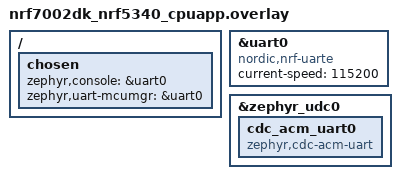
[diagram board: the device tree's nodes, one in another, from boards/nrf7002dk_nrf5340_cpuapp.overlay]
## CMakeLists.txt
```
# SPDX-License-Identifier: Apache-2.0

cmake_minimum_required(VERSION 3.20.0)
find_package(Zephyr REQUIRED HINTS $ENV{ZEPHYR_BASE})
project(central_multilink)

target_sources(app PRIVATE
  src/main.c
  src/listing.c
  src/led_control.c
  src/uart_comm.c
  src/central_multilink.c
)
target_include_directories(app PRIVATE inc)
zephyr_library_include_directories(${ZEPHYR_BASE}/samples/bluetooth)
```

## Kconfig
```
# Copyright (c) 2021 Nordic Semiconductor ASA
# SPDX-License-Identifier: Apache-2.0

mainmenu "Bluetooth: Central Multilink"

config SAMPLE_CONN_ITERATIONS
	int "Connection iterations"
	range 0 255
	default 0
	help
	  Number of times to connect and disconnect to peripheral_identity
	  sample.

source "Kconfig.zephyr"
```

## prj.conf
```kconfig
CONFIG_BT=y
CONFIG_BT_CENTRAL=y
CONFIG_BT_AUTO_PHY_UPDATE=n
CONFIG_BT_PRIVACY=y
CONFIG_BT_OBSERVER=y
CONFIG_BT_MAX_CONN=62
CONFIG_BT_SCAN_WITH_IDENTITY=y
# CONFIG_BT_EXT_ADV=y
# Increase the number of buffers to avoid deadlock when running out of buffers
CONFIG_BT_BUF_CMD_TX_COUNT=2

CONFIG_BT_GATT_CLIENT=y

# CONFIG_BT_SMP=y
# CONFIG_BT_MAX_PAIRED=62

# CONFIG_BT_EXT_ADV=y
# CONFIG_BT_CTLR_ADV_EXT=y

# LED and PWM configuration
CONFIG_PWM=y
CONFIG_LED=y
CONFIG_LED_PWM=y
CONFIG_GPIO=y
CONFIG_DK_LIBRARY=y

# Enable UART driver (existing - for console on UART0)
CONFIG_SERIAL=y
CONFIG_UART_CONSOLE=y
CONFIG_UART_ASYNC_API=y

# USB Device Support (NEW - for nRF5340 USB)
CONFIG_USB_DEVICE_STACK=y
CONFIG_USB_DEVICE_PRODUCT="nRF5340 Sensor Hub"
CONFIG_USB_DEVICE_MANUFACTURER="Your Company"
CONFIG_USB_DEVICE_VID=0x2FE3
CONFIG_USB_DEVICE_PID=0x0001
CONFIG_USB_DEVICE_INITIALIZE_AT_BOOT=y

# USB CDC ACM (NEW)
CONFIG_USB_CDC_ACM=y
CONFIG_UART_LINE_CTRL=y

# Logging (NEW - useful for debugging both interfaces)
CONFIG_LOG=y
CONFIG_PRINTK=y
```

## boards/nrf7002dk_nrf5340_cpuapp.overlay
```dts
/ {
    chosen {
        zephyr,console = &uart0;        // Keep console on UART0
        zephyr,uart-mcumgr = &uart0;
    };
};

&uart0 {
    status = "okay";
    current-speed = <115200>;
    compatible = "nordic,nrf-uarte";
};

&zephyr_udc0 {
    cdc_acm_uart0: cdc_acm_uart0 {
        compatible = "zephyr,cdc-acm-uart";
    };
};
```

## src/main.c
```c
/* main.c - Application main entry point */

/*
 * Copyright (c) 2021 Nordic Semiconductor ASA
 *
 * SPDX-License-Identifier: Apache-2.0
 */

#include <stdint.h>
#include <main.h>

int init_central(uint8_t max_conn, uint8_t iterations);

int main(void)
{
	(void)init_central(CONFIG_BT_MAX_CONN, CONFIG_SAMPLE_CONN_ITERATIONS);
	// Initialize USB CDC ACM
	return 0;
}
```

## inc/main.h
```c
#include <zephyr/types.h>
#include <stdint.h>
#include <stddef.h>
#include <stdbool.h>
#include <errno.h>
#include <string.h>
#include <zephyr/kernel.h>
#include <zephyr/sys/printk.h>

#include <zephyr/bluetooth/bluetooth.h>
#include <zephyr/bluetooth/hci.h>
#include <zephyr/bluetooth/conn.h>
#include <zephyr/bluetooth/uuid.h>
#include <zephyr/bluetooth/gatt.h>
#include <zephyr/sys/byteorder.h>
#include <zephyr/sys/slist.h>
#include <zephyr/drivers/gpio.h>
#include <zephyr/drivers/led.h>
#include <zephyr/device.h>
#include <zephyr/devicetree.h>
#include <dk_buttons_and_leds.h>
#include <zephyr/drivers/uart.h>

/* Environmental Sensing Service UUIDs */
#define BT_UUID_ESS_VAL 0x181a
#define BT_UUID_TEMP_CHAR_VAL     0x2a6e
#define BT_UUID_PRESSURE_CHAR_VAL 0x2a6d
#define BT_UUID_HUMIDITY_CHAR_VAL 0x2a6f

#define SCAN_INTERVAL 0x0010 /* 10 ms */
#define SCAN_WINDOW   0x0010 /* 10 ms */
#define INIT_INTERVAL 0x0010 /* 10 ms */
#define INIT_WINDOW   0x0010 /* 10 ms */
#define CONN_INTERVAL 0x0320 /* 1000 ms */
#define CONN_LATENCY  0
#define CONN_TIMEOUT  MIN(MAX((CONN_INTERVAL * 125 * \
			       MAX(CONFIG_BT_MAX_CONN, 6) / 1000), 10), 3200)

/* LED Configuration */
#define LED_PWM_NODE_ID	 DT_COMPAT_GET_ANY_STATUS_OKAY(pwm_leds)
#define MAX_BRIGHTNESS	100
#define PWM_FADE_DELAY	50
#define BLINK_INTERVAL  2000  /* 2 seconds between blinks */
#define BLINK_DURATION  200   /* 200ms blink duration */
#define CON_STATUS_LED  DK_LED1  /* GPIO LED1 as fallback */

/* Manual Whitelist system */
#define MAX_DEVICE_LIST 200  /* Increased from 50 to handle more devices */
#define MAX_MANUAL_WHITELIST 10  /* Maximum number of manually whitelisted devices */

/* UART */
#define UART_LABEL DT_LABEL(DT_NODELABEL(uart0))
#define MAX_SEEED_CONN 4  // Max number of simultaneous Seeed BLE devices

/* Manual whitelist entry structure */
typedef struct {
    char mac[18];  // "AA:BB:CC:DD:EE:FF\0"
    bool active;
} manual_whitelist_entry_t;

/* Whitelist/Blacklist Structs*/
typedef enum {
	DEVICE_STATUS_UNKNOWN = 0,
	DEVICE_STATUS_WHITELISTED,
	DEVICE_STATUS_BLACKLISTED
} device_status_t;

typedef struct device_entry {
	bt_addr_le_t addr;
	device_status_t status;
	uint8_t disconnect_count;
	uint8_t connect_count;
	uint8_t scan_found_count;
	bool has_made_param_request;
	sys_snode_t node;
} device_entry_t;

/* GATT Client structures for Environmental Sensing Service */
struct gatt_ess_data {
	struct bt_conn *conn;
	uint16_t temp_handle;
	uint16_t pressure_handle;
	uint16_t humidity_handle;
	uint16_t temp_ccc_handle;
	uint16_t pressure_ccc_handle;
	uint16_t humidity_ccc_handle;
	bool temp_notify_enabled;
	bool pressure_notify_enabled;
	bool humidity_notify_enabled;
};

extern struct gatt_ess_data ess_data[CONFIG_BT_MAX_CONN];

/* Packet structure sent over UART */
typedef struct __packed {
    char device_addr[BT_ADDR_LE_STR_LEN];  // Seeed device ID or slot index
    int16_t value_a;
    uint32_t value_b;
    uint16_t value_c;
} sensor_packet_t;

typedef struct __packed {
    char mac_addr[30];   // ASCII MAC string, null-padded
    int8_t rssi;         // signed 8-bit RSSI
    uint8_t connected;   // 1 = connected to this central, 0 = not connected
} rssi_packet_t;

/* Per-connection state */
typedef struct {
    struct bt_conn *conn;
    sensor_packet_t data;
    bool a_ready;
    bool b_ready;
    bool c_ready;
    bool active;
    uint8_t subscribed_mask;  // bitmask of subscribed characteristics (bit0=A, bit1=B, bit2=C)
} seeed_conn_t;



void start_scan(void);
void start_passive_scan(void);
device_status_t get_device_status(const bt_addr_le_t *addr);
void add_device_to_whitelist(const bt_addr_le_t *addr);
void remove_device_from_whitelist(const bt_addr_le_t *addr);
void add_device_to_blacklist(const bt_addr_le_t *addr);
bool is_device_whitelisted(const bt_addr_le_t *addr);
bool is_device_blacklisted(const bt_addr_le_t *addr);
bool is_device_manually_whitelisted(const bt_addr_le_t *addr);
device_entry_t *get_or_create_device_entry(const bt_addr_le_t *addr);
void track_device_connect(const bt_addr_le_t *addr);
void track_device_disconnect(const bt_addr_le_t *addr, uint8_t reason);

/* Manual whitelist management functions */
void init_manual_whitelist(void);
bool add_mac_to_manual_whitelist(const char *mac_str);
bool remove_mac_from_manual_whitelist(const char *mac_str);

/* LED control functions */
void led_work_handler(struct k_work *work);
void led_timer_handler(struct k_timer *timer);
void start_led_breathing(void);
void start_led_blinking(uint8_t device_count);
void stop_led_effects(void);
void flash_data_led(void);

#if defined(CONFIG_BT_GATT_CLIENT) /* GATT Client functions */
extern struct bt_gatt_exchange_params mtu_exchange_params[CONFIG_BT_MAX_CONN];
extern struct bt_gatt_discover_params discover_params[CONFIG_BT_MAX_CONN];
extern struct bt_gatt_subscribe_params subscribe_params[CONFIG_BT_MAX_CONN * 3]; /* 3 characteristics per connection */

void mtu_exchange_cb(struct bt_conn *conn, uint8_t err, struct bt_gatt_exchange_params *params);
int mtu_exchange(struct bt_conn *conn);
uint8_t ess_notify_cb(struct bt_conn *conn, struct bt_gatt_subscribe_params *params, const void *data, uint16_t length);
uint8_t ess_discover_func(struct bt_conn *conn, const struct bt_gatt_attr *attr, struct bt_gatt_discover_params *params);
void ess_discover_complete(struct bt_conn *conn, int err);
int ess_discover_services(struct bt_conn *conn);
int ess_subscribe_notifications(struct bt_conn *conn);
#endif /* CONFIG_BT_GATT_CLIENT */

#if defined(CONFIG_BT_SMP)
void security_changed(struct bt_conn *conn, bt_security_t level, enum bt_security_err err);
#endif

#if defined(CONFIG_BT_USER_PHY_UPDATE)
void le_phy_updated(struct bt_conn *conn, struct bt_conn_le_phy_info *param);
#endif

#if defined(CONFIG_BT_USER_DATA_LEN_UPDATE)
void le_data_len_updated(struct bt_conn *conn, struct bt_conn_le_data_len_info *info);
#endif

/* Central Multilink BLE Functions*/
void connected(struct bt_conn *conn, uint8_t reason);
void disconnected(struct bt_conn *conn, uint8_t reason);
bool app_le_param_req(struct bt_conn *conn, struct bt_le_conn_param *param);
void app_le_param_updated(struct bt_conn *conn, uint16_t interval, uint16_t latency, uint16_t timeout);
void remote_info(struct bt_conn *conn, void *data);
void disconnect(struct bt_conn *conn, void* data);
int init_central(uint8_t max_conn, uint8_t iterations);
extern struct bt_conn_cb conn_callbacks;

/* UART Control Functions */
void uart_send_data(const uint8_t *data, size_t len);
void on_ble_connected(struct bt_conn *conn, char* addr);
void on_ble_disconnected(struct bt_conn *conn);
seeed_conn_t *find_node_by_conn(struct bt_conn *conn);
seeed_conn_t *find_node_by_mac_addr(char* addr);
void try_send_packet(seeed_conn_t *node);
void ble_value_a_received(struct bt_conn *conn, int16_t val);
void ble_value_b_received(struct bt_conn *conn, uint32_t val);
void ble_value_c_received(struct bt_conn *conn, uint16_t val);

/* Whitelist/Blacklist system variables*/
extern sys_slist_t whitelist;
extern sys_slist_t blacklist;
extern device_entry_t device_entries[MAX_DEVICE_LIST];
extern uint8_t device_entry_count;

extern struct bt_conn *conn_connecting;
extern uint8_t conn_count_max;
extern uint8_t volatile conn_count;
extern bool volatile is_disconnecting;

/* Manual whitelist variables */
extern manual_whitelist_entry_t manual_whitelist[MAX_MANUAL_WHITELIST];
extern uint8_t manual_whitelist_count;

/* LED control variables */
extern const struct device *led_pwm;
extern int16_t current_brightness;
extern bool brightness_increasing;
extern struct k_timer led_timer;
extern struct k_work led_work;
extern bool led_blink_state;
extern uint8_t blink_count;

/* UART Variables */
extern const struct device *uart_dev;
extern seeed_conn_t seeed_nodes[MAX_SEEED_CONN];

int usb_init(void);
void usb_send_data(const uint8_t *data, size_t len);
void usb_send_framed(uint8_t type, const uint8_t *payload, size_t len);
void send_rssi_report(const char *mac17, int8_t rssi, uint8_t connected_flag);
```

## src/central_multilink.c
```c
/* main.c - Application main entry point */

/*
 * Copyright (c) 2021 Nordic Semiconductor ASA
 * Copyright (c) 2015-2016 Intel Corporation
 *
 * SPDX-License-Identifier: Apache-2.0
 */

#include "main.h"

struct gatt_ess_data ess_data[CONFIG_BT_MAX_CONN];

#if defined(CONFIG_BT_GATT_CLIENT)
void mtu_exchange_cb(struct bt_conn *conn, uint8_t err,
			    struct bt_gatt_exchange_params *params)
{
	printk("MTU exchange %u %s (%u)\n", bt_conn_index(conn),
	       err == 0U ? "successful" : "failed", bt_gatt_get_mtu(conn));
}

struct bt_gatt_exchange_params mtu_exchange_params[CONFIG_BT_MAX_CONN];

/* GATT Client discovery and notification structures */
struct bt_gatt_discover_params discover_params[CONFIG_BT_MAX_CONN];
struct bt_gatt_subscribe_params subscribe_params[CONFIG_BT_MAX_CONN * 3]; /* 3 characteristics per connection */

int mtu_exchange(struct bt_conn *conn)
{
	uint8_t conn_index;
	int err;

	conn_index = bt_conn_index(conn);

	printk("MTU (%u): %u\n", conn_index, bt_gatt_get_mtu(conn));

	mtu_exchange_params[conn_index].func = mtu_exchange_cb;

	err = bt_gatt_exchange_mtu(conn, &mtu_exchange_params[conn_index]);
	if (err) {
		printk("MTU exchange failed (err %d)", err);
	} else {
		printk("Exchange pending...");
	}

	return err;
}

/* GATT Client implementation for Environmental Sensing Service */
uint8_t ess_notify_cb(struct bt_conn *conn, struct bt_gatt_subscribe_params *params, const void *data, uint16_t length)
{
	uint8_t conn_index = bt_conn_index(conn);
	char addr[BT_ADDR_LE_STR_LEN];
	
	bt_addr_le_to_str(bt_conn_get_dst(conn), addr, sizeof(addr));
	
	if (!data || length == 0) {
		printk("ESS notification from %s: subscription ended\n", addr);
		return BT_GATT_ITER_STOP;
	}
	
	/* Determine which characteristic this notification is for */
	if (params->value_handle == ess_data[conn_index].temp_handle) {
		int16_t temp_val = sys_get_le32(data);
		uint32_t temp_celsius_int = (temp_val * 100) / 10000;  /* Convert to integer with 2 decimal places */
		uint32_t temp_celsius_frac = ((temp_val * 100) % 10000) / 100;
		printk("ESS [%s] Temperature: %d.%02d°C (raw: %d)\n", addr, temp_celsius_int, temp_celsius_frac, temp_val);
		ble_value_a_received(conn, temp_val);
		flash_data_led();  /* Flash LED2 to indicate data reception */
	} else if (params->value_handle == ess_data[conn_index].pressure_handle) {
		uint32_t press_val = sys_get_le32(data);
		uint32_t press_pa_int = press_val / 100;
		uint32_t press_pa_frac = (press_val % 100);
		printk("ESS [%s] Pressure: %u.%02u Pa (raw: %u)\n", addr, press_pa_int, press_pa_frac, press_val);
		ble_value_b_received(conn, press_val);
		flash_data_led();  /* Flash LED2 to indicate data reception */
	} else if (params->value_handle == ess_data[conn_index].humidity_handle) {
		uint16_t humid_val = sys_get_le32(data);
		uint32_t humid_percent_int = humid_val / 100;
		uint32_t humid_percent_frac = humid_val % 100;
		printk("ESS [%s] Humidity: %u.%02u%% (raw: %u)\n", addr, humid_percent_int, humid_percent_frac, humid_val);
		ble_value_c_received(conn, humid_val);
		flash_data_led();  /* Flash LED2 to indicate data reception */
	} else {
		printk("ESS [%s] Unknown notification: handle=0x%04x, len=%u\n", 
		       addr, params->value_handle, length);
	}
	
	return BT_GATT_ITER_CONTINUE;
}

uint8_t ess_discover_func(struct bt_conn *conn, const struct bt_gatt_attr *attr, struct bt_gatt_discover_params *params)
{
	uint8_t conn_index = bt_conn_index(conn);
	char addr[BT_ADDR_LE_STR_LEN];
	
	bt_addr_le_to_str(bt_conn_get_dst(conn), addr, sizeof(addr));
	
	if (!attr) {
		printk("ESS discovery complete for %s\n", addr);
		ess_discover_complete(conn, 0);
		return BT_GATT_ITER_STOP;
	}
	
	if (params->type == BT_GATT_DISCOVER_PRIMARY) {
		const struct bt_gatt_service_val *gatt_service = (const struct bt_gatt_service_val *)attr->user_data;
		
		if (gatt_service->uuid->type == BT_UUID_TYPE_16) {
			uint16_t uuid16 = BT_UUID_16(gatt_service->uuid)->val;
			printk("ESS [%s] Found service: 0x%04x, handle range: 0x%04x-0x%04x\n", 
			       addr, uuid16, attr->handle, gatt_service->end_handle);
			
			if (uuid16 == BT_UUID_ESS_VAL) {
				printk("ESS [%s] Found Environmental Sensing Service! Starting characteristic discovery...\n", addr);
				
				/* Found ESS service, now discover characteristics */
				discover_params[conn_index].type = BT_GATT_DISCOVER_CHARACTERISTIC;
				discover_params[conn_index].uuid = NULL;
				discover_params[conn_index].start_handle = attr->handle;
				discover_params[conn_index].end_handle = gatt_service->end_handle;
				discover_params[conn_index].func = ess_discover_func;
				
				int err = bt_gatt_discover(conn, &discover_params[conn_index]);
				if (err) {
					printk("ESS [%s] Characteristic discovery failed: %d\n", addr, err);
					ess_discover_complete(conn, err);
					return BT_GATT_ITER_STOP;
				}
				return BT_GATT_ITER_STOP;
			}
		}
	} else if (params->type == BT_GATT_DISCOVER_CHARACTERISTIC) {
		struct bt_gatt_chrc *chrc = (struct bt_gatt_chrc *)attr->user_data;
		
		if (chrc->uuid->type == BT_UUID_TYPE_16) {
			uint16_t uuid16 = BT_UUID_16(chrc->uuid)->val;
			printk("ESS [%s] Found characteristic: 0x%04x, handle=0x%04x, properties=0x%02x\n", 
			       addr, uuid16, chrc->value_handle, chrc->properties);
			
			if (uuid16 == BT_UUID_TEMP_CHAR_VAL) {
				ess_data[conn_index].temp_handle = chrc->value_handle;
				printk("ESS [%s] Found Temperature characteristic: handle=0x%04x\n", 
				       addr, chrc->value_handle);
			} else if (uuid16 == BT_UUID_PRESSURE_CHAR_VAL) {
				ess_data[conn_index].pressure_handle = chrc->value_handle;
				printk("ESS [%s] Found Pressure characteristic: handle=0x%04x\n", 
				       addr, chrc->value_handle);
			} else if (uuid16 == BT_UUID_HUMIDITY_CHAR_VAL) {
				ess_data[conn_index].humidity_handle = chrc->value_handle;
				printk("ESS [%s] Found Humidity characteristic: handle=0x%04x\n", 
				       addr, chrc->value_handle);
			}
		}
	} else if (params->type == BT_GATT_DISCOVER_DESCRIPTOR) {
		if (attr->uuid->type == BT_UUID_TYPE_16 && 
		    BT_UUID_16(attr->uuid)->val == BT_UUID_GATT_CCC_VAL) {
			
			printk("ESS [%s] Found CCC descriptor: handle=0x%04x\n", addr, attr->handle);
			
			/* Determine which CCC this is based on the handle */
			if (attr->handle == ess_data[conn_index].temp_handle + 1) {
				ess_data[conn_index].temp_ccc_handle = attr->handle;
				printk("ESS [%s] Found Temperature CCC: handle=0x%04x\n", addr, attr->handle);
			} else if (attr->handle == ess_data[conn_index].pressure_handle + 1) {
				ess_data[conn_index].pressure_ccc_handle = attr->handle;
				printk("ESS [%s] Found Pressure CCC: handle=0x%04x\n", addr, attr->handle);
			} else if (attr->handle == ess_data[conn_index].humidity_handle + 1) {
				ess_data[conn_index].humidity_ccc_handle = attr->handle;
				printk("ESS [%s] Found Humidity CCC: handle=0x%04x\n", addr, attr->handle);
			}
		}
	}
	
	return BT_GATT_ITER_CONTINUE;
}

void ess_discover_complete(struct bt_conn *conn, int err)
{
	char addr[BT_ADDR_LE_STR_LEN];
	
	bt_addr_le_to_str(bt_conn_get_dst(conn), addr, sizeof(addr));
	
	if (err) {
		printk("ESS discovery failed for %s: %d\n", addr, err);
		return;
	}
	
	printk("ESS discovery completed for %s\n", addr);
	
	/* Subscribe to notifications */
	ess_subscribe_notifications(conn);
}

int ess_discover_services(struct bt_conn *conn)
{
	uint8_t conn_index = bt_conn_index(conn);
	char addr[BT_ADDR_LE_STR_LEN];
	int err;
	
	bt_addr_le_to_str(bt_conn_get_dst(conn), addr, sizeof(addr));
	
	/* Initialize ESS data for this connection */
	ess_data[conn_index].conn = conn;
	ess_data[conn_index].temp_handle = 0;
	ess_data[conn_index].pressure_handle = 0;
	ess_data[conn_index].humidity_handle = 0;
	ess_data[conn_index].temp_ccc_handle = 0;
	ess_data[conn_index].pressure_ccc_handle = 0;
	ess_data[conn_index].humidity_ccc_handle = 0;
	ess_data[conn_index].temp_notify_enabled = false;
	ess_data[conn_index].pressure_notify_enabled = false;
	ess_data[conn_index].humidity_notify_enabled = false;
	
	/* Start with discovering all primary services to see what's available */
	discover_params[conn_index].type = BT_GATT_DISCOVER_PRIMARY;
	discover_params[conn_index].uuid = NULL;  /* Discover all services */
	discover_params[conn_index].start_handle = 0x0001;
	discover_params[conn_index].end_handle = 0xffff;
	discover_params[conn_index].func = ess_discover_func;
	
	printk("Starting service discovery for %s\n", addr);
	
	err = bt_gatt_discover(conn, &discover_params[conn_index]);
	if (err) {
		printk("Service discovery start failed for %s: %d\n", addr, err);
		return err;
	}
	
	return 0;
}

int ess_subscribe_notifications(struct bt_conn *conn)
{
	uint8_t conn_index = bt_conn_index(conn);
	char addr[BT_ADDR_LE_STR_LEN];
	int err;
	int param_count = 0;
	seeed_conn_t *node = find_node_by_conn(conn); // Might need to add error handling if node not found
    node->subscribed_mask = 0;
	
	bt_addr_le_to_str(bt_conn_get_dst(conn), addr, sizeof(addr));
	
	printk("ESS [%s] Attempting to subscribe to notifications...\n", addr);
	printk("ESS [%s] Found handles - Temp: 0x%04x, Pressure: 0x%04x, Humidity: 0x%04x\n", 
	       addr, ess_data[conn_index].temp_handle, ess_data[conn_index].pressure_handle, ess_data[conn_index].humidity_handle);
	
	/* Subscribe to temperature notifications */
	if (ess_data[conn_index].temp_handle) {
		/* Assume CCC handle is characteristic handle + 1 */
		uint16_t ccc_handle = ess_data[conn_index].temp_handle + 1;
		
		subscribe_params[conn_index * 3 + param_count].notify = ess_notify_cb;
		subscribe_params[conn_index * 3 + param_count].value = BT_GATT_CCC_NOTIFY;
		subscribe_params[conn_index * 3 + param_count].value_handle = ess_data[conn_index].temp_handle;
		subscribe_params[conn_index * 3 + param_count].ccc_handle = ccc_handle;
		
		err = bt_gatt_subscribe(conn, &subscribe_params[conn_index * 3 + param_count]);
		if (err) {
			printk("ESS [%s] Temperature subscription failed: %d\n", addr, err);
		} else {
			printk("ESS [%s] Temperature notifications subscribed (handle=0x%04x, ccc=0x%04x)\n", 
			       addr, ess_data[conn_index].temp_handle, ccc_handle);
			ess_data[conn_index].temp_notify_enabled = true;
		}
		param_count++;
		if (!err) node->subscribed_mask |= BIT(0); // value_a subscribed

	}
	
	/* Subscribe to pressure notifications */
	if (ess_data[conn_index].pressure_handle) {
		/* Assume CCC handle is characteristic handle + 1 */
		uint16_t ccc_handle = ess_data[conn_index].pressure_handle + 1;
		
		subscribe_params[conn_index * 3 + param_count].notify = ess_notify_cb;
		subscribe_params[conn_index * 3 + param_count].value = BT_GATT_CCC_NOTIFY;
		subscribe_params[conn_index * 3 + param_count].value_handle = ess_data[conn_index].pressure_handle;
		subscribe_params[conn_index * 3 + param_count].ccc_handle = ccc_handle;
		
		err = bt_gatt_subscribe(conn, &subscribe_params[conn_index * 3 + param_count]);
		if (err) {
			printk("ESS [%s] Pressure subscription failed: %d\n", addr, err);
		} else {
			printk("ESS [%s] Pressure notifications subscribed (handle=0x%04x, ccc=0x%04x)\n", 
			       addr, ess_data[conn_index].pressure_handle, ccc_handle);
			ess_data[conn_index].pressure_notify_enabled = true;
		}
		param_count++;
		if (!err) node->subscribed_mask |= BIT(1); // value_b subscribed
	}
	
	/* Subscribe to humidity notifications */
	if (ess_data[conn_index].humidity_handle) {
		/* Assume CCC handle is characteristic handle + 1 */
		uint16_t ccc_handle = ess_data[conn_index].humidity_handle + 1;
		
		subscribe_params[conn_index * 3 + param_count].notify = ess_notify_cb;
		subscribe_params[conn_index * 3 + param_count].value = BT_GATT_CCC_NOTIFY;
		subscribe_params[conn_index * 3 + param_count].value_handle = ess_data[conn_index].humidity_handle;
		subscribe_params[conn_index * 3 + param_count].ccc_handle = ccc_handle;
		
		err = bt_gatt_subscribe(conn, &subscribe_params[conn_index * 3 + param_count]);
		if (err) {
			printk("ESS [%s] Humidity subscription failed: %d\n", addr, err);
		} else {
			printk("ESS [%s] Humidity notifications subscribed (handle=0x%04x, ccc=0x%04x)\n", 
			       addr, ess_data[conn_index].humidity_handle, ccc_handle);
			ess_data[conn_index].humidity_notify_enabled = true;
		}
		param_count++;
		if (!err) node->subscribed_mask |= BIT(2); // value_c subscribed
	}
	
	if (param_count == 0) {
		printk("ESS [%s] No characteristics found for subscription\n", addr);
		return -ENOENT;
	}
	
	printk("ESS [%s] Successfully subscribed to %d characteristics\n", addr, param_count);
	return 0;
}

#endif /* CONFIG_BT_GATT_CLIENT */

void connected(struct bt_conn *conn, uint8_t reason)
{
	char addr[BT_ADDR_LE_STR_LEN];
	const bt_addr_le_t *conn_addr = bt_conn_get_dst(conn);

	bt_addr_le_to_str(conn_addr, addr, sizeof(addr));

	if (reason) {
		printk("Failed to connect to %s (%u)\n", addr, reason);

		bt_conn_unref(conn_connecting);
		conn_connecting = NULL;

		start_scan();
		return;
	}

	conn_connecting = NULL;

	/* Track this connection */
	track_device_connect(conn_addr);

	conn_count++;
	if (conn_count < conn_count_max) {
		start_scan();
	}

	printk("Connected (%u): %s\n", conn_count, addr);

	/* Start LED blinking effect based on device count */
	start_led_blinking(conn_count);

	on_ble_connected(conn, addr);

#if defined(CONFIG_BT_SMP)
	int err = bt_conn_set_security(conn, BT_SECURITY_L2);

	if (err) {
		printk("Failed to set security (%d).\n", err);
	}
#endif

#if defined(CONFIG_BT_GATT_CLIENT)
	mtu_exchange(conn);
	/* Start ESS discovery after a short delay to allow MTU exchange to complete */
	k_sleep(K_MSEC(100));
	ess_discover_services(conn);
#endif
}

void disconnected(struct bt_conn *conn, uint8_t reason)
{
	char addr[BT_ADDR_LE_STR_LEN];
	const bt_addr_le_t *conn_addr = bt_conn_get_dst(conn);

	bt_addr_le_to_str(conn_addr, addr, sizeof(addr));

	printk("Disconnected: %s, reason 0x%02x %s\n", addr, reason, bt_hci_err_to_str(reason));

#if defined(CONFIG_BT_GATT_CLIENT)
	/* Clean up ESS subscriptions */
	uint8_t conn_index = bt_conn_index(conn);
	if (conn_index < CONFIG_BT_MAX_CONN) {
		/* Unsubscribe from all notifications */
		for (int i = 0; i < 3; i++) {
			if (subscribe_params[conn_index * 3 + i].value_handle) {
				bt_gatt_unsubscribe(conn, &subscribe_params[conn_index * 3 + i]);
			}
		}
		/* Clear ESS data */
		memset(&ess_data[conn_index], 0, sizeof(ess_data[conn_index]));
	}
#endif

	/* Track this disconnection */
	track_device_disconnect(conn_addr, reason);

	/* Update SEEED connection state */
	on_ble_disconnected(conn);

	bt_conn_unref(conn);

	if ((conn_count == 1U) && (is_disconnecting || (reason == BT_HCI_ERR_CONN_FAIL_TO_ESTAB))) {
		is_disconnecting = false;
		start_scan();
	}
	conn_count--;

	/* Update LED effect based on remaining connections */
	if (conn_count == 0) {
		/* No devices connected, start breathing effect */
		start_led_breathing();
	} else {
		/* Still have devices connected, update blinking pattern */
		start_led_blinking(conn_count);
	}
}

bool app_le_param_req(struct bt_conn *conn, struct bt_le_conn_param *param)
{
	char addr[BT_ADDR_LE_STR_LEN];
	const bt_addr_le_t *conn_addr = bt_conn_get_dst(conn);
	device_entry_t *entry;

	bt_addr_le_to_str(conn_addr, addr, sizeof(addr));

	printk("LE conn param req: %s int (0x%04x, 0x%04x) lat %d to %d\n",
	       addr, param->interval_min, param->interval_max, param->latency,
	       param->timeout);

	/* Mark that this device has made a parameter request */
	entry = get_or_create_device_entry(conn_addr);
	if (entry) {
		entry->has_made_param_request = true;
	}

	/* Manual whitelist mode - no automatic whitelisting/blacklisting based on parameters */
	printk("Device %s connection parameters received (manual whitelist mode)\n", addr);

	return true;
}

void app_le_param_updated(struct bt_conn *conn, uint16_t interval, uint16_t latency, uint16_t timeout)
{
	char addr[BT_ADDR_LE_STR_LEN];

	bt_addr_le_to_str(bt_conn_get_dst(conn), addr, sizeof(addr));

	printk("LE conn param updated: %s int 0x%04x lat %d to %d\n",
	       addr, interval, latency, timeout);
}

struct bt_conn_cb conn_callbacks = {
	.connected = connected,
	.disconnected = disconnected,
	.le_param_req = app_le_param_req,
	.le_param_updated = app_le_param_updated,

#if defined(CONFIG_BT_SMP)
	.security_changed = security_changed,
#endif

#if defined(CONFIG_BT_USER_PHY_UPDATE)
	.le_phy_updated = le_phy_updated,
#endif /* CONFIG_BT_USER_PHY_UPDATE */

#if defined(CONFIG_BT_USER_DATA_LEN_UPDATE)
	.le_data_len_updated = le_data_len_updated,
#endif /* CONFIG_BT_USER_DATA_LEN_UPDATE */
};

void remote_info(struct bt_conn *conn, void *data)
{
	struct bt_conn_remote_info remote_info;
	char addr[BT_ADDR_LE_STR_LEN];
	int err;

	bt_addr_le_to_str(bt_conn_get_dst(conn), addr, sizeof(addr));

	printk("Get remote info %s...\n", addr);
	err = bt_conn_get_remote_info(conn, &remote_info);
	if (err) {
		printk("Failed remote info %s.\n", addr);
		return;
	}
	printk("success.\n");

	uint8_t *actual_count = (void *)data;

	(*actual_count)++;
}

void disconnect(struct bt_conn *conn, void* data)
{
	char addr[BT_ADDR_LE_STR_LEN];
	int err;

	bt_addr_le_to_str(bt_conn_get_dst(conn), addr, sizeof(addr));

	printk("Disconnecting %s...\n", addr);
	err = bt_conn_disconnect(conn, BT_HCI_ERR_REMOTE_USER_TERM_CONN);
	if (err) {
		printk("Failed disconnection %s.\n", addr);
		return;
	}
	on_ble_disconnected(conn);
	printk("success.\n");
}

int init_central(uint8_t max_conn, uint8_t iterations)
{
	int err;

	conn_count_max = max_conn;

	/* Initialize LED PWM device */
	led_pwm = DEVICE_DT_GET(LED_PWM_NODE_ID);
	if (!device_is_ready(led_pwm)) {
		printk("PWM LED device not ready, LED effects disabled\n");
		led_pwm = NULL;
	} else {
		printk("PWM LED device initialized successfully\n");
	}

	/* Initialize LED timer and work */
	k_timer_init(&led_timer, led_timer_handler, NULL);
	k_work_init(&led_work, led_work_handler);

	/* Initialize DK LEDs for fallback */
	err = dk_leds_init();
	if (err) {
		printk("DK LEDs init failed (err %d)\n", err);
	}
	
	if (usb_init() != 0) {
        printk("Failed to initialize USB CDC ACM\n");
        // Continue anyway - UART console still works
    }

	/* Initialize whitelist/blacklist system */
	init_manual_whitelist();
	device_entry_count = 0;

	err = bt_enable(NULL);
	if (err) {
		printk("Bluetooth init failed (err %d)\n", err);
		return err;
	}

	printk("Bluetooth initialized\n");
	printk("Manual Whitelist system initialized\n");
	
	printk("Only manually whitelisted devices will be connected to\n");

	bt_conn_cb_register(&conn_callbacks);

	/* Start LED breathing effect (no devices connected initially) */
	start_led_breathing();
	
	/* Test LED to make sure it's working */
	if (led_pwm && device_is_ready(led_pwm)) {
		led_set_brightness(led_pwm, 0, MAX_BRIGHTNESS);
		k_sleep(K_SECONDS(1));
		led_set_brightness(led_pwm, 0, 0);
	}

	start_scan();
	// start_passive_scan(); // Scanning for RSSI advertisments

	while (true) {
		while (conn_count < conn_count_max) {
			k_sleep(K_MSEC(10));
		}

		is_disconnecting = true;

		/* Let us perform version exchange on all connections to ensure
		 * there is actual communication.
		 */
		uint8_t actual_count = 0U;

		bt_conn_foreach(BT_CONN_TYPE_LE, remote_info, &actual_count);
		if (actual_count < conn_count_max) {
			k_sleep(K_MSEC(10));

			continue;
		}

		/* Lets wait sufficiently to ensure a stable connection
		 * before starting to disconnect for next iteration.
		 */
		k_sleep(K_SECONDS(60));

		if (!iterations) {
			break;
		}
		iterations--;
		printk("Iterations remaining: %u\n", iterations);

		/* Device needing multiple connections is the one
		 * initiating the disconnects.
		 */
		if (conn_count_max > 1U) {
			printk("Disconnecting all...\n");
			bt_conn_foreach(BT_CONN_TYPE_LE, disconnect, NULL);
		} else {
			printk("Wait for disconnections...\n");
		}

		while (is_disconnecting) {
			k_sleep(K_MSEC(10));
		}
		printk("All disconnected.\n");
	}

	return 0;
}


#if defined(CONFIG_BT_SMP)
void security_changed(struct bt_conn *conn, bt_security_t level,
			     enum bt_security_err err)
{
	char addr[BT_ADDR_LE_STR_LEN];

	bt_addr_le_to_str(bt_conn_get_dst(conn), addr, sizeof(addr));

	if (!err) {
		printk("Security changed: %s level %u\n", addr, level);
	} else {
		printk("Security failed: %s level %u err %d %s\n", addr, level,
		       err, bt_security_err_to_str(err));
	}
}
#endif

#if defined(CONFIG_BT_USER_PHY_UPDATE)
void le_phy_updated(struct bt_conn *conn,
			   struct bt_conn_le_phy_info *param)
{
	char addr[BT_ADDR_LE_STR_LEN];

	bt_addr_le_to_str(bt_conn_get_dst(conn), addr, sizeof(addr));

	printk("LE PHY Updated: %s Tx 0x%x, Rx 0x%x\n", addr, param->tx_phy,
	       param->rx_phy);
}
#endif /* CONFIG_BT_USER_PHY_UPDATE */

#if defined(CONFIG_BT_USER_DATA_LEN_UPDATE)
void le_data_len_updated(struct bt_conn *conn,
				struct bt_conn_le_data_len_info *info)
{
	char addr[BT_ADDR_LE_STR_LEN];

	bt_addr_le_to_str(bt_conn_get_dst(conn), addr, sizeof(addr));

	printk("Data length updated: %s max tx %u (%u us) max rx %u (%u us)\n",
	       addr, info->tx_max_len, info->tx_max_time, info->rx_max_len,
	       info->rx_max_time);
}
#endif /* CONFIG_BT_USER_DATA_LEN_UPDATE */
```

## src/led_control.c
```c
#include "main.h"

/* LED control variables */
const struct device *led_pwm;
int16_t current_brightness = 0;
bool brightness_increasing = true;
struct k_timer led_timer;
struct k_work led_work;
bool led_blink_state = false;
uint8_t blink_count = 0;



/* LED control function implementations */
void led_work_handler(struct k_work *work)
{
	if (conn_count == 0) {
		/* Breathing effect when no devices connected */
		if (brightness_increasing) {
			current_brightness += 5;
			if (current_brightness >= MAX_BRIGHTNESS) {
				current_brightness = MAX_BRIGHTNESS;
				brightness_increasing = false;
			}
		} else {
			current_brightness -= 5;
			if (current_brightness <= 0) {
				current_brightness = 0;
				brightness_increasing = true;
			}
		}
		
		/* Set PWM brightness for LED1 (pwm-led0, index 0) */
		if (led_pwm && device_is_ready(led_pwm)) {
			led_set_brightness(led_pwm, 0, current_brightness);
		} else {
			/* Fallback to GPIO LED - simple on/off for breathing effect */
			if (current_brightness > 50) {
				dk_set_led_on(CON_STATUS_LED);
			} else {
				dk_set_led_off(CON_STATUS_LED);
			}
		}
	} else {
		/* Blinking effect based on device count */
		if (led_blink_state) {
			/* Turn LED on */
			if (led_pwm && device_is_ready(led_pwm)) {
				led_set_brightness(led_pwm, 0, MAX_BRIGHTNESS);
			} else {
				dk_set_led_on(CON_STATUS_LED);
			}
			led_blink_state = false;
			/* Schedule next blink */
			k_timer_start(&led_timer, K_MSEC(BLINK_DURATION), K_NO_WAIT);
		} else {
			/* Turn LED off */
			if (led_pwm && device_is_ready(led_pwm)) {
				led_set_brightness(led_pwm, 0, 0);
			} else {
				dk_set_led_off(CON_STATUS_LED);
			}
			led_blink_state = true;
			blink_count++;
			
			if (blink_count >= conn_count) {
				/* Finished blinking for all devices, wait 2 seconds */
				blink_count = 0;
				k_timer_start(&led_timer, K_MSEC(BLINK_INTERVAL), K_NO_WAIT);
			} else {
				/* Continue blinking */
				k_timer_start(&led_timer, K_MSEC(BLINK_DURATION), K_NO_WAIT);
			}
		}
	}
}

void led_timer_handler(struct k_timer *timer)
{
	k_work_submit(&led_work);
}

void start_led_breathing(void)
{
	stop_led_effects();
	current_brightness = 0;
	brightness_increasing = true;
	k_timer_start(&led_timer, K_MSEC(PWM_FADE_DELAY), K_MSEC(PWM_FADE_DELAY));
}

void start_led_blinking(uint8_t device_count)
{
	stop_led_effects();
	blink_count = 0;
	led_blink_state = true;
	/* Start first blink immediately */
	k_work_submit(&led_work);
}

void stop_led_effects(void)
{
	k_timer_stop(&led_timer);
	blink_count = 0;
	led_blink_state = false;
}

void flash_data_led(void)
{
	/* Flash LED2 briefly to indicate data reception */
	dk_set_led_on(DK_LED2);
	k_sleep(K_MSEC(50));  /* 50ms flash */
	dk_set_led_off(DK_LED2);
}
```

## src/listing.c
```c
#include "main.h"

sys_slist_t whitelist;
sys_slist_t blacklist;
device_entry_t device_entries[MAX_DEVICE_LIST];
uint8_t device_entry_count;

struct bt_conn *conn_connecting;
uint8_t conn_count_max;
uint8_t volatile conn_count;
bool volatile is_disconnecting;

/* Dynamic manual whitelist */
manual_whitelist_entry_t manual_whitelist[MAX_MANUAL_WHITELIST];
uint8_t manual_whitelist_count = 0;

/* Initialize manual whitelist with default MACs */
void init_manual_whitelist(void)
{
    /* Initialize all entries as inactive */
    for (int i = 0; i < MAX_MANUAL_WHITELIST; i++) {
        manual_whitelist[i].active = false;
        memset(manual_whitelist[i].mac, 0, 18);
    }
    
    /* OPTIONAL: Add default MACs here */
    const char* default_macs[] = {
        "D2:29:B2:D0:66:FC",
        "7C:DF:A1:FB:72:7D"
    };
    
    int default_count = sizeof(default_macs) / sizeof(default_macs[0]);
    for (int i = 0; i < default_count && i < MAX_MANUAL_WHITELIST; i++) {
        strncpy(manual_whitelist[i].mac, default_macs[i], 17);
        manual_whitelist[i].mac[17] = '\0';
        manual_whitelist[i].active = true;
        manual_whitelist_count++;
    }
    
    printk("Manual whitelist initialized with %d devices\n", manual_whitelist_count);
}

/* Add MAC to manual whitelist */
bool add_mac_to_manual_whitelist(const char *mac_str)
{
    if (mac_str == NULL) {
        printk("Cannot add NULL MAC to whitelist\n");
        return false;
    }
    
    /* Check if already exists */
    for (int i = 0; i < MAX_MANUAL_WHITELIST; i++) {
        if (manual_whitelist[i].active && 
            strncmp(manual_whitelist[i].mac, mac_str, 17) == 0) {
            printk("MAC %s already in manual whitelist\n", mac_str);
            return true;
        }
    }
    
    /* Find empty slot */
    for (int i = 0; i < MAX_MANUAL_WHITELIST; i++) {
        if (!manual_whitelist[i].active) {
            strncpy(manual_whitelist[i].mac, mac_str, 17);
            manual_whitelist[i].mac[17] = '\0';
            manual_whitelist[i].active = true;
            manual_whitelist_count++;
            printk("Added %s to manual whitelist (count: %d)\n", 
                   mac_str, manual_whitelist_count);
            return true;
        }
    }
    
    printk("Manual whitelist full! Cannot add %s\n", mac_str);
    return false;
}

/* Remove MAC from manual whitelist */
bool remove_mac_from_manual_whitelist(const char *mac_str)
{
    if (mac_str == NULL) {
        printk("Cannot remove NULL MAC from whitelist\n");
        return false;
    }
    
    for (int i = 0; i < MAX_MANUAL_WHITELIST; i++) {
        if (manual_whitelist[i].active && 
            strncmp(manual_whitelist[i].mac, mac_str, 17) == 0) {
            manual_whitelist[i].active = false;
            memset(manual_whitelist[i].mac, 0, 18);
            manual_whitelist_count--;
            printk("Removed %s from manual whitelist (count: %d)\n", 
                   mac_str, manual_whitelist_count);
            return true;
        }
    }
    
    printk("MAC %s not found in manual whitelist\n", mac_str);
    return false;
}

/* Check if device is in manual whitelist */
bool is_device_manually_whitelisted(const bt_addr_le_t *addr)
{
    char addr_str[BT_ADDR_LE_STR_LEN];
    bt_addr_le_to_str(addr, addr_str, sizeof(addr_str));
    
    /* Extract just the MAC address part (first 17 chars) */
    char mac_only[18];
    strncpy(mac_only, addr_str, 17);
    mac_only[17] = '\0';
    
    /* Check against manual whitelist */
    for (int i = 0; i < MAX_MANUAL_WHITELIST; i++) {
        if (manual_whitelist[i].active && 
            strncmp(manual_whitelist[i].mac, mac_only, 17) == 0) {
            return true;
        }
    }
    
    return false;
}

/* Whitelist/Blacklist management functions */
device_status_t get_device_status(const bt_addr_le_t *addr)
{
	sys_snode_t *node;
	device_entry_t *entry;

	/* Check whitelist first */
	SYS_SLIST_FOR_EACH_NODE(&whitelist, node) {
		entry = CONTAINER_OF(node, device_entry_t, node);
		if (bt_addr_le_cmp(&entry->addr, addr) == 0) {
			return DEVICE_STATUS_WHITELISTED;
		}
	}

	/* Check blacklist */
	SYS_SLIST_FOR_EACH_NODE(&blacklist, node) {
		entry = CONTAINER_OF(node, device_entry_t, node);
		if (bt_addr_le_cmp(&entry->addr, addr) == 0) {
			return DEVICE_STATUS_BLACKLISTED;
		}
	}

	return DEVICE_STATUS_UNKNOWN;
}

device_entry_t *find_or_create_device_entry(const bt_addr_le_t *addr)
{
	sys_snode_t *node;
	device_entry_t *entry;

	/* First, check if device already exists in either list */
	SYS_SLIST_FOR_EACH_NODE(&whitelist, node) {
		entry = CONTAINER_OF(node, device_entry_t, node);
		if (bt_addr_le_cmp(&entry->addr, addr) == 0) {
			return entry;
		}
	}

	SYS_SLIST_FOR_EACH_NODE(&blacklist, node) {
		entry = CONTAINER_OF(node, device_entry_t, node);
		if (bt_addr_le_cmp(&entry->addr, addr) == 0) {
			return entry;
		}
	}

	/* Create new entry if we have space */
	if (device_entry_count < MAX_DEVICE_LIST) {
		entry = &device_entries[device_entry_count++];
		bt_addr_le_copy(&entry->addr, addr);
		entry->status = DEVICE_STATUS_UNKNOWN;
		entry->disconnect_count = 0;
		entry->connect_count = 0;
		entry->scan_found_count = 0;
		entry->has_made_param_request = false;
		return entry;
	}

	return NULL;
}

void add_device_to_whitelist(const bt_addr_le_t *addr)
{
	device_entry_t *entry = find_or_create_device_entry(addr);
	if (!entry) {
		printk("Warning: Cannot add device to whitelist - list full\n");
		return;
	}

	/* Remove from blacklist if it exists there */
	sys_slist_find_and_remove(&blacklist, &entry->node);

	/* Add to whitelist if not already there */
	if (!sys_slist_find(&whitelist, &entry->node, NULL)) {
		sys_slist_append(&whitelist, &entry->node);
		entry->status = DEVICE_STATUS_WHITELISTED;
	}
}

void remove_device_from_whitelist(const bt_addr_le_t *addr)
{
	device_entry_t *entry = find_or_create_device_entry(addr);
	if (!entry) {
		printk("Warning: Cannot remove device from whitelist - Not in Whitelist\n");
		return;
	}

	/* Remove from whitelist if it exists there */
	sys_slist_find_and_remove(&whitelist, &entry->node);

	entry->status = DEVICE_STATUS_UNKNOWN;
}

void add_device_to_blacklist(const bt_addr_le_t *addr)
{
	device_entry_t *entry = find_or_create_device_entry(addr);
	if (!entry) {
		printk("Warning: Cannot add device to blacklist - list full\n");
		return;
	}

	/* Remove from whitelist if it exists there */
	sys_slist_find_and_remove(&whitelist, &entry->node);

	/* Add to blacklist if not already there */
	if (!sys_slist_find(&blacklist, &entry->node, NULL)) {
		sys_slist_append(&blacklist, &entry->node);
		entry->status = DEVICE_STATUS_BLACKLISTED;
	}
}

bool is_device_whitelisted(const bt_addr_le_t *addr)
{
	return get_device_status(addr) == DEVICE_STATUS_WHITELISTED;
}

bool is_device_blacklisted(const bt_addr_le_t *addr)
{
	return get_device_status(addr) == DEVICE_STATUS_BLACKLISTED;
}

device_entry_t *get_or_create_device_entry(const bt_addr_le_t *addr)
{
	return find_or_create_device_entry(addr);
}

void track_device_connect(const bt_addr_le_t *addr)
{
	device_entry_t *entry = get_or_create_device_entry(addr);
	if (entry) {
		entry->connect_count++;
		char addr_str[BT_ADDR_LE_STR_LEN];
		bt_addr_le_to_str(addr, addr_str, sizeof(addr_str));
		printk("Track connect: %s (conn_count=%d, disconnect_count=%d, has_param_req=%d)\n",
		       addr_str, entry->connect_count, entry->disconnect_count, entry->has_made_param_request);
	}
}

void track_device_disconnect(const bt_addr_le_t *addr, uint8_t reason)
{
	device_entry_t *entry = get_or_create_device_entry(addr);
	if (entry) {
		entry->disconnect_count++;
		char addr_str[BT_ADDR_LE_STR_LEN];
		bt_addr_le_to_str(addr, addr_str, sizeof(addr_str));
		printk("Track disconnect: %s (conn_count=%d, disconnect_count=%d, has_param_req=%d)\n",
		       addr_str, entry->connect_count, entry->disconnect_count, entry->has_made_param_request);
		
		/* Manual whitelist mode - no automatic blacklisting */
		printk("Device %s disconnected (manual whitelist mode - no auto blacklisting)\n", addr_str);
	}
}

// -----------------------------------------------------------------------------
// UNIFIED SCAN CALLBACK - Handles both connectable and non-connectable advertisements
// -----------------------------------------------------------------------------
static void unified_scan_callback(const bt_addr_le_t *addr, int8_t rssi,
                                  uint8_t type, struct net_buf_simple *ad)
{
	char addr_str[BT_ADDR_LE_STR_LEN];
	bt_addr_le_to_str(addr, addr_str, sizeof(addr_str));
	
	/* Extract MAC-only part (first 17 chars) */
	char mac_only[18];
	strncpy(mac_only, addr_str, 17);
	mac_only[17] = '\0';

	/* ===== HANDLE NON-CONNECTABLE BEACONS (RSSI Monitoring) ===== */
	/* Process beacons FIRST and independently of connection state */
	if (type == BT_GAP_ADV_TYPE_ADV_NONCONN_IND) {
		/* Parse advertisement data to find "SEEED_TEST" name */
		bool is_seeed_test = false;
		struct net_buf_simple temp_buf = *ad;

		while (temp_buf.len > 1) {
			uint8_t len = net_buf_simple_pull_u8(&temp_buf);
			if (len == 0 || len > temp_buf.len)
				break;
			uint8_t type_field = net_buf_simple_pull_u8(&temp_buf);

			if (type_field == BT_DATA_NAME_COMPLETE) {
				char name[32];
				size_t nc = MIN((size_t)(len - 1), sizeof(name) - 1);
				memcpy(name, temp_buf.data, nc);
				name[nc] = '\0';
				if (strcmp(name, "SEEED_TEST") == 0) {
					is_seeed_test = true;
					break;
				}
			}
			net_buf_simple_pull(&temp_buf, len - 1);
		}

		/* Only process if it's a SEEED_TEST beacon */
		if (is_seeed_test) {
			/* Check if this MAC corresponds to a connected node */
			seeed_conn_t *node = find_node_by_mac_addr(mac_only);
			uint8_t connected_flag = (node != NULL) ? 1 : 0;

			/* Send RSSI report for all SEEED_TEST beacons, regardless of whitelist */
			send_rssi_report(mac_only, (int8_t)rssi, connected_flag);

			/* Optional: Only log whitelisted devices to reduce console spam */
			if (is_device_manually_whitelisted(addr)) {
				printk("[BEACON] %s RSSI: %d dBm (connected=%d)\n", 
				       mac_only, rssi, connected_flag);
			}
		}
		
		/* Always return after processing beacons - don't try to connect to them */
		return;
	}

	/* ===== HANDLE CONNECTABLE ADVERTISEMENTS (Device Connection) ===== */
	/* Only process connectable advertisements if not currently connecting */
	if (conn_connecting) {
		return;
	}

	/* We're only interested in connectable events */
	if (type != BT_GAP_ADV_TYPE_ADV_IND &&
	    type != BT_GAP_ADV_TYPE_ADV_DIRECT_IND &&
	    type != BT_GAP_ADV_TYPE_EXT_ADV) {
		return;
	}

	/* Connect only to devices in close proximity */
	if (rssi < -100) {
		return;
	}

	/* Only connect to manually whitelisted devices */
	if (!is_device_manually_whitelisted(addr)) {
		return;
	}

	printk("Device found (manually whitelisted): %s (RSSI %d) - attempting connection\n", 
	       addr_str, rssi);

	/* Attempt connection */
	struct bt_conn_le_create_param create_param = {
		.options = BT_CONN_LE_OPT_NONE,
		.interval = INIT_INTERVAL,
		.window = INIT_WINDOW,
		.interval_coded = 0,
		.window_coded = 0,
		.timeout = 0,
	};
	struct bt_le_conn_param conn_param = {
		.interval_min = CONN_INTERVAL,
		.interval_max = CONN_INTERVAL,
		.latency = CONN_LATENCY,
		.timeout = CONN_TIMEOUT,
	};

	printk("Stopping scan to attempt connection to %s\n", addr_str);
	int err = bt_le_scan_stop();
	if (err != 0) {
		printk("Failed to stop scanning (err %d)\n", err);
		return;
	}

	err = bt_conn_le_create(addr, &create_param, &conn_param, &conn_connecting);
	if (err) {
		printk("Create conn to %s failed (%d)\n", addr_str, err);
		start_scan();
	}
}

void start_scan(void)
{
	struct bt_le_scan_param scan_param = {
		.type       = BT_LE_SCAN_TYPE_PASSIVE,
		.options    = BT_LE_SCAN_OPT_NONE,  /* REMOVED duplicate filtering for RSSI tracking */
		.interval   = SCAN_INTERVAL,
		.window     = SCAN_WINDOW,
	};
	int err;

	err = bt_le_scan_start(&scan_param, unified_scan_callback);
	if (err && err != -EALREADY) {
		printk("Scanning failed to start (err %d)\n", err);
		return;
	}

	printk("Unified scanning started (handles both connection and RSSI monitoring)\n");
}
```
